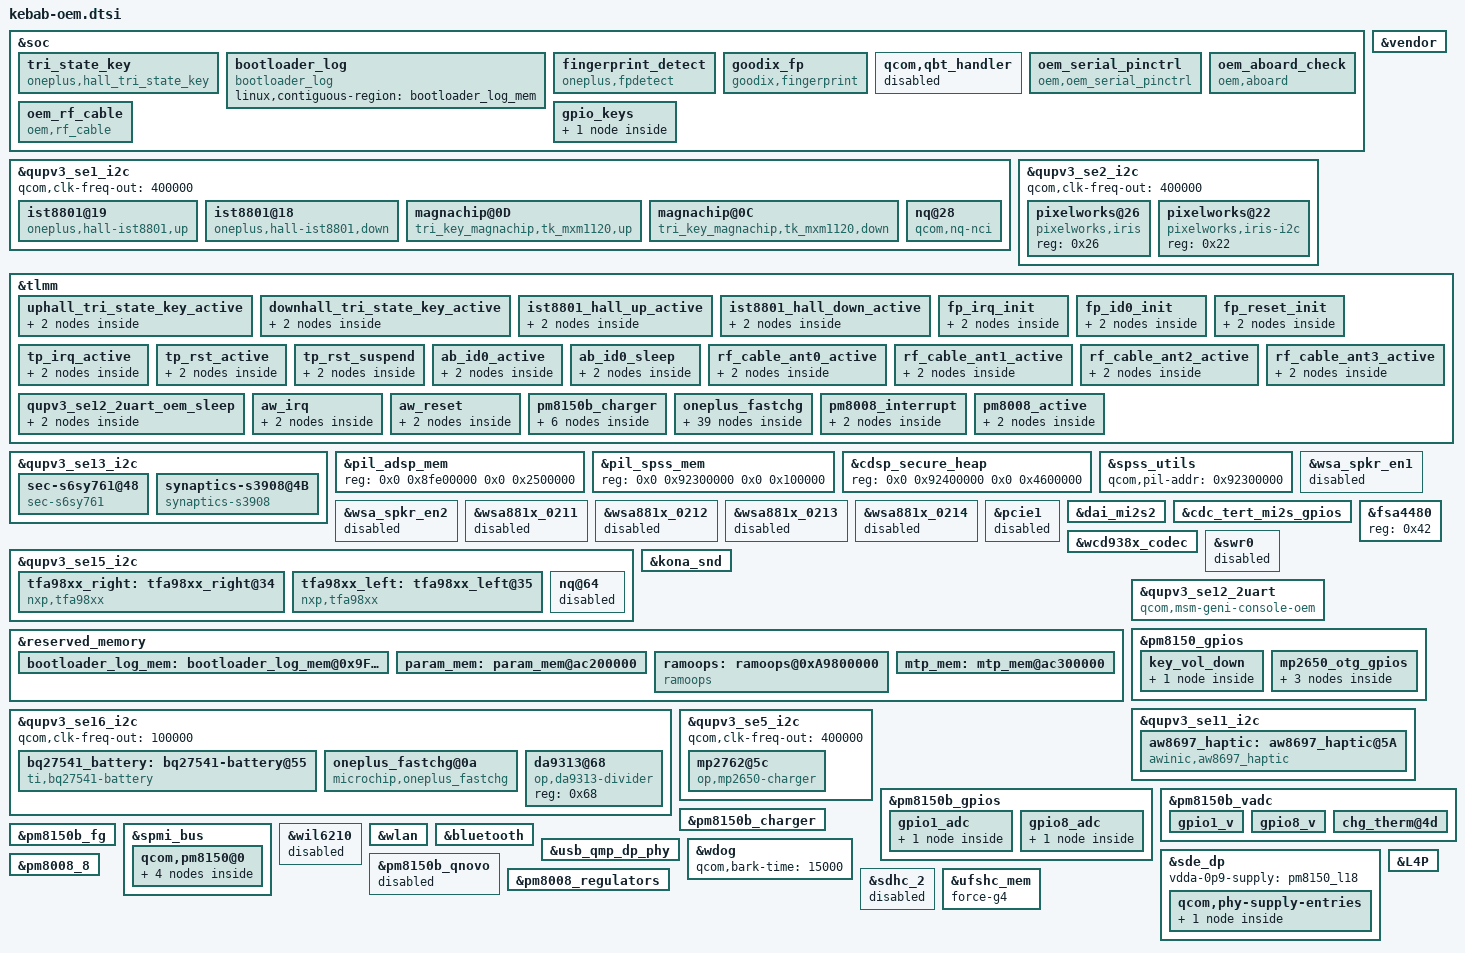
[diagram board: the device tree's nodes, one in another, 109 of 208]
/*this is for oem project dtsi*/
&soc {
	tri_state_key:tri_state_key {
		compatible = "oneplus,hall_tri_state_key";
		status = "ok";
		interrupt-parent = <&tlmm>;
		project_info = <1>;
	};

	bootloader_log {
		compatible = "bootloader_log";
		linux,contiguous-region = <&bootloader_log_mem>;
	};

	fingerprint_detect:fingerprint_detect {
		oneplus,19805;
		compatible = "oneplus,fpdetect";
		fp-gpio-id0 = <&tlmm 77 0>;
		pinctrl-names = "fp_id_init";
		pinctrl-0 = <&fp_id0_init>;
	};

	goodix_fp:goodix_fp {
		compatible = "goodix,fingerprint";
		interrupt-parent = <&tlmm>;
		//vdd-3v2-supply = <&pm8998_l22>;
		//vdd-voltage = <3200000 3200000>;
		//vdd-current = <50000>;
		fp-gpio-irq = <&tlmm 23 0x00>;
		fp-gpio-reset = <&tlmm 68 0x00>;
		fppower-supply = <&pm8150_l16>; 
		status = "okay";
	};

	qcom,qbt_handler {
		status = "disabled";
	};
};

&vendor {
	/delete-node/ extcon_usb1;
};


&qupv3_se1_i2c {
	status = "ok";
	qcom,clk-freq-out = <400000>;
	ist8801@19 {
		compatible = "oneplus,hall-ist8801,up";
		reg = <0x19>;
		dhall,id = <1>;
		vdd-supply = <&pm8150a_l10>;
		interrupt-parent = <&tlmm>;
		interrups = <157 0x02>;
		dhall,irq-gpio = <&tlmm 157 0x2008>;
		pinctrl-names = "ist8801_hall_up_active";
		pinctrl-0 = <&ist8801_hall_up_active>;
	};
	ist8801@18 {
		compatible = "oneplus,hall-ist8801,down";
		reg = <0x18>;
		dhall,id = <2>;
		vdd-supply = <&pm8150a_l10>;
		interrupt-parent = <&tlmm>;
		interrups = <158 0x02>;
		dhall,irq-gpio = <&tlmm 158 0x2008>;
		pinctrl-names = "ist8801_hall_down_active";
		pinctrl-0 = <&ist8801_hall_down_active>;
	};
};
&qupv3_se1_i2c {
	status = "ok";
	qcom,clk-freq-out = <400000>;
	magnachip@0D {
		compatible = "tri_key_magnachip,tk_mxm1120,up";
		reg = <0x0D>;
		vdd-supply = <&pm8150a_l10>;
		magnachip,init-interval = <200>;
		interrupt-parent = <&tlmm>;
		interrups = <157 0x02>;
		dhall,irq-gpio = <&tlmm 157 0x2008>;
		pinctrl-names = "uphall_tri_state_key_active";
		pinctrl-0 = <&uphall_tri_state_key_active>;
	};
	magnachip@0C {
		compatible = "tri_key_magnachip,tk_mxm1120,down";
		reg = <0x0C>;
		vdd-supply = <&pm8150a_l10>;
		magnachip,init-interval = <200>;
		interrupt-parent = <&tlmm>;
		interrups = <158 0x02>;
		dhall,irq-gpio = <&tlmm 158 0x2008>;
		pinctrl-names = "downhall_tri_state_key_active";
		pinctrl-0 = <&downhall_tri_state_key_active>;
	};
};

&qupv3_se2_i2c {
       status = "ok";
       qcom,clk-freq-out = <400000>;
       pixelworks@26 {  //i2c: 22, i3c: 26
               status = "ok";
               compatible = "pixelworks,iris";
               reg = <0x26>;
        };

       pixelworks@22 {  //i2c: 22, i3c: 26
               status = "ok";
               compatible = "pixelworks,iris-i2c";
               reg = <0x22>;
        };
};


&tlmm {
	uphall_tri_state_key_active: uphall_tri_state_key_active {
		mux {
			pins = "gpio157";
			function = "gpio";
		};
		config {
			pins = "gpio157";
			drive-strength = <2>;
			bias-pull-up;
		};
	};
	downhall_tri_state_key_active: downhall_tri_state_key_active {
		mux {
			pins = "gpio158";
			function = "gpio";
		};
		config {
			pins = "gpio158";
			drive-strength = <2>;
			bias-pull-up;
		};
	};
};
&tlmm {
	ist8801_hall_up_active: ist8801_hall_up_active {
		mux {
			pins = "gpio157";
			function = "gpio";
		};
		config {
			pins = "gpio157";
			drive-strength = <2>;
			bias-pull-up;
		};
	};
	ist8801_hall_down_active: ist8801_hall_down_active {
		mux {
			pins = "gpio158";
			function = "gpio";
		};
		config {
			pins = "gpio158";
			drive-strength = <2>;
			bias-pull-up;
		};
	};

	fp_irq_init: fp_irq_init {
		mux {
			pins = "gpio23";
			function = "gpio";
		};

		config {
			pins = "gpio23";
			drive-strength = <2>;
			bias-disable;
			input-enable;
		};
	};

	fp_id0_init: fp_id0_init {
		mux {
			pins = "gpio77";
			function = "gpio";
		};

		config {
			pins = "gpio77";
			drive-strength = <2>;
			bias-disable; /* No Pull */
			input-enable;
		};
	};

	fp_reset_init: fp_reset_init {
		mux {
			pins = "gpio131";
			function = "gpio";
		};

		config {
			pins = "gpio131";
			drive-strength = <8>;
			bias-pull-up;
		};
	};
};
&qupv3_se13_i2c {
	status = "ok";
	sec-s6sy761@48 {
		compatible = "sec-s6sy761";
		reg = <0x48>;
		project-name = "19811";
		chip-name = "SY761";
		module_id = <7>;
		reset-gpio = <&tlmm 38 0x00>;
		irq-gpio = <&tlmm 39 0x2008>;
		vdd_2v8-supply = <&pm8150_l13>;                 //set 3.3 by ldo
		vdd_2v8_volt = <3008000>;
		vcc_1v8-supply = <&pm8150a_l1>;
	//	enable1v8_gpio = <&tlmm 119 0x00>;               //set 1.8v by
		touchpanel,display-coords = <1439 3119>;
		touchpanel,panel-coords = <1439 3119>;
		touchpanel,tx-rx-num = <17 37>;
		//edge_limit_support = <1>;
		//spurious_fingerprint_support = <1>;
		//charger_pump_support = <1>;
		black_gesture_support = <1>;
		//black_gesture_test_support = <1>;
		game_switch_support = <1>;
		face_detect_support = <1>;
		touch_hold_support = <1>;
		touchpanel,max-num-support = <10>;
		charge_detect_support = <1>;
		//lcd_trigger_fp_check = <1>;
		module_id_support = <1>;
		pinctrl-names = "pin_set_high", "pin_set_low";
		pinctrl-0 = <&tp_irq_active &tp_rst_active>;
		pinctrl-1 = <&tp_rst_suspend>;
		//touchpanel,int-mode = <1>;
	};
};
&qupv3_se13_i2c {
	status = "ok";
	synaptics-s3908@4B {
		compatible = "synaptics-s3908";
		reg = <0x4B>;
		project-name = "19805";
		chip-name = "S3908";
		module_id = <7>;
		reset-gpio = <&tlmm 38 0x00>;
		irq-gpio = <&tlmm 39 0x2008>;
		vdd_2v8-supply = <&pm8150_l13>;                 //set 3.3 by ldo
		vdd_2v8_volt = <3008000>;
		vcc_1v8-supply = <&pm8150a_l1>;
		touchpanel,display-coords = <1079 2399>;
		touchpanel,panel-coords = <1079 2399>;
		touchpanel,tx-rx-num = <16 36>;
		//edge_limit_support = <1>;
		//spurious_fingerprint_support = <1>;
		//charger_pump_support = <1>;
		black_gesture_support = <1>;
		//black_gesture_test_support = <1>;
		game_switch_support = <1>;
		lcd_refresh_rate_switch = <1>;
		charge_detect_support = <1>;
		face_detect_support = <1>;
		touch_hold_support = <1>;
		touchpanel,max-num-support = <10>;
		report_flow_unlock_support = <1>;
		pinctrl-names = "pin_set_high", "pin_set_low";
		pinctrl-0 = <&tp_irq_active &tp_rst_active>;
		pinctrl-1 = <&tp_rst_suspend>;
		touchpanel,int-mode = <1>;
		panel = <&dsi_boe_nt37800_fhd_dsc_cmd &dsi_samsung_dd305_dsc_cmd &dsi_samsung_amb655x_dsc_cmd>;
	};
};
&tlmm {
	tp_irq_active: tp_irq_active {
		mux {
			pins = "gpio39";
			function = "gpio";
		};
		config {
			pins = "gpio39";
			drive-strength = <8>;
			bias-disable;
			input-enable;
		};
	};
	tp_rst_active: tp_rst_active {
		mux {
			pins = "gpio38";
			function = "gpio";
		};
		config {
			pins = "gpio38";
			drive-strength = <8>;
			bias-pull-up;
		};
	};
	tp_rst_suspend: tp_rst_suspend {
		mux {
			pins = "gpio38";
			function = "gpio";
		};
		config {
			pins = "gpio38";
			drive-strength = <8>;
			bias-pull-down;
		};
	};
};

&pil_adsp_mem {
	reg = <0x0 0x8fe00000 0x0 0x2500000>;
};

&pil_spss_mem {
	reg = <0x0 0x92300000 0x0 0x100000>;
};

&cdsp_secure_heap {
	reg = <0x0 0x92400000 0x0 0x4600000>;
};

&spss_utils {
	qcom,pil-addr = <0x92300000>; // backward compatible
};

&wsa_spkr_en1 {
	status = "disabled";
};

&wsa_spkr_en2 {
	status = "disabled";
};

&wsa881x_0211 {
	status = "disabled";
};

&wsa881x_0212 {
	status = "disabled";
};

&wsa881x_0213 {
	status = "disabled";
};

&wsa881x_0214 {
	status = "disabled";
};

&pcie1 {
    status = "disabled";
};

&qupv3_se15_i2c {
	tfa98xx_right: tfa98xx_right@34 {
		compatible = "nxp,tfa98xx";
		reg = <0x34>;
		reset-gpio = <&tlmm 91 0>;
		nxp,sb-ver-3P5 = <1>;
		status = "ok";
	};

	tfa98xx_left: tfa98xx_left@35 {
		compatible = "nxp,tfa98xx";
		reg = <0x35>;
		reset-gpio = <&tlmm 99 0>;
		nxp,sb-ver-3P5 = <1>;
		status = "ok";
	};

	nq@64 {
		status = "disabled";
	};
};

&dai_mi2s2 {
	qcom,msm-mi2s-rx-lines = <2>;
	qcom,msm-mi2s-tx-lines = <1>;
};

&cdc_tert_mi2s_gpios {
	pinctrl-0 = <&tert_mi2s_sck_active &tert_mi2s_ws_active
			&tert_mi2s_sd0_active &tert_mi2s_sd1_active>;
	pinctrl-1 = <&tert_mi2s_sck_sleep &tert_mi2s_ws_sleep
			&tert_mi2s_sd0_sleep &tert_mi2s_sd1_sleep>;
};

&fsa4480 {
	reg = <0x42>;
};

&wcd938x_codec {
	qcom,cdc-vdd-mic-bias-voltage = <3300000 3600000>;
	qcom,cdc-micbias2-mv = <2700>;
};

&swr0 {
	status = "disabled";
};

&kona_snd {
	//enable low-latency loopback
	asoc-platform = <&pcm0>, <&pcm1>, <&pcm2>, <&voip>, <&voice>,
			<&loopback1>, <&compress>, <&hostless>,
			<&afe>, <&lsm>, <&routing>, <&compr>,
			<&pcm_noirq>;
	qcom,afe-rxtx-lb = <1>;
	// default audio routing for 3-mic
	qcom,audio-routing =
		"AMIC1", "MIC BIAS1",
		"MIC BIAS1", "Analog Mic1",
		"AMIC2", "MIC BIAS2",
		"MIC BIAS2", "Analog Mic2",
		"AMIC3", "MIC BIAS3",
		"MIC BIAS3", "Analog Mic3",
		"AMIC4", "MIC BIAS3",
		"MIC BIAS3", "Analog Mic4",
		"AMIC5", "MIC BIAS4",
		"MIC BIAS4", "Analog Mic5",
		"TX DMIC0", "MIC BIAS1",
		"MIC BIAS1", "Digital Mic0",
		"TX DMIC1", "MIC BIAS1",
		"MIC BIAS1", "Digital Mic1",
		"TX DMIC2", "MIC BIAS3",
		"MIC BIAS3", "Digital Mic2",
		"TX DMIC3", "MIC BIAS4",
		"MIC BIAS4", "Digital Mic3",
		"TX DMIC4", "MIC BIAS4",
		"MIC BIAS4", "Digital Mic4",
		"TX DMIC5", "MIC BIAS4",
		"MIC BIAS4", "Digital Mic5",
		"IN1_HPHL", "HPHL_OUT",
		"IN2_HPHR", "HPHR_OUT",
		"IN3_AUX", "AUX_OUT",
		"TX SWR_ADC0", "ADC1_OUTPUT",
		"TX SWR_ADC1", "ADC2_OUTPUT",
		"TX SWR_ADC2", "ADC3_OUTPUT",
		"TX SWR_ADC3", "ADC4_OUTPUT",
		"TX SWR_DMIC0", "DMIC1_OUTPUT",
		"TX SWR_DMIC1", "DMIC2_OUTPUT",
		"TX SWR_DMIC2", "DMIC3_OUTPUT",
		"TX SWR_DMIC3", "DMIC4_OUTPUT",
		"TX SWR_DMIC4", "DMIC5_OUTPUT",
		"TX SWR_DMIC5", "DMIC6_OUTPUT",
		"TX SWR_DMIC6", "DMIC7_OUTPUT",
		"TX SWR_DMIC7", "DMIC8_OUTPUT",
		"WSA SRC0_INP", "SRC0",
		"WSA_TX DEC0_INP", "TX DEC0 MUX",
		"WSA_TX DEC1_INP", "TX DEC1 MUX",
		"RX_TX DEC0_INP", "TX DEC0 MUX",
		"RX_TX DEC1_INP", "TX DEC1 MUX",
		"RX_TX DEC2_INP", "TX DEC2 MUX",
		"RX_TX DEC3_INP", "TX DEC3 MUX",
		"VA_AIF1 CAP", "VA_SWR_CLK",
		"VA_AIF2 CAP", "VA_SWR_CLK",
		"VA_AIF3 CAP", "VA_SWR_CLK",
		"VA MIC BIAS1", "Digital Mic0",
		"VA MIC BIAS1", "Digital Mic1",
		"VA MIC BIAS3", "Digital Mic2",
		"VA MIC BIAS4", "Digital Mic3",
		"VA MIC BIAS4", "Digital Mic4",
		"VA MIC BIAS4", "Digital Mic5",
		"VA DMIC0", "VA MIC BIAS1",
		"VA DMIC1", "VA MIC BIAS1",
		"VA DMIC2", "VA MIC BIAS3",
		"VA DMIC3", "VA MIC BIAS4",
		"VA DMIC4", "VA MIC BIAS4",
		"VA DMIC5", "VA MIC BIAS4",
		"VA SWR_ADC0", "VA_SWR_CLK",
		"VA SWR_ADC1", "VA_SWR_CLK",
		"VA SWR_ADC2", "VA_SWR_CLK",
		"VA SWR_ADC3", "VA_SWR_CLK",
		"VA SWR_MIC0", "VA_SWR_CLK",
		"VA SWR_MIC1", "VA_SWR_CLK",
		"VA SWR_MIC2", "VA_SWR_CLK",
		"VA SWR_MIC3", "VA_SWR_CLK",
		"VA SWR_MIC4", "VA_SWR_CLK",
		"VA SWR_MIC5", "VA_SWR_CLK",
		"VA SWR_MIC6", "VA_SWR_CLK",
		"VA SWR_MIC7", "VA_SWR_CLK",
		"VA SWR_ADC0", "ADC1_OUTPUT",
		"VA SWR_ADC1", "ADC2_OUTPUT",
		"VA SWR_ADC2", "ADC3_OUTPUT",
		"VA SWR_ADC3", "ADC4_OUTPUT",
		"VA SWR_MIC0", "DMIC1_OUTPUT",
		"VA SWR_MIC1", "DMIC2_OUTPUT",
		"VA SWR_MIC2", "DMIC3_OUTPUT",
		"VA SWR_MIC3", "DMIC4_OUTPUT",
		"VA SWR_MIC4", "DMIC5_OUTPUT",
		"VA SWR_MIC5", "DMIC6_OUTPUT",
		"VA SWR_MIC6", "DMIC7_OUTPUT",
		"VA SWR_MIC7", "DMIC8_OUTPUT";

	//change to NC
	qcom,msm-mbhc-hphl-swh = <0>;
	qcom,wsa-max-devs = <0>;
	qcom,wsa-devs;
	//qcom,codec-aux-devs = <-2>;

	//qcom,tert-mi2s-gpios = <&tert_mi2s_gpios>;
	qcom,msm-mbhc-usbc-audio-supported = <1>;
	qcom,msm-mbhc-use-usbc-detect = <1>;
	qcom,msm-mbhc-hs-mic-max-threshold-mv = <2550>;
};

&reserved_memory {

	bootloader_log_mem: bootloader_log_mem@0x9FFF7000 {
		reg = <0 0x9FFF7000 0 0x00009000>;
		label = "bootloader_log_mem";
	};

	param_mem: param_mem@ac200000 {
		reg = <0 0xAC200000 0 0x00100000>;
		label = "param_mem";
	};

	/*after cdsp_secure_heap we add a offset to ignore change address need reconfig*/
	ramoops: ramoops@0xA9800000 {
		compatible = "ramoops";
		reg = <0 0xA9800000 0 0x00400000>;
		record-size =  <0x40000>; //256x1024
		console-size = <0x40000>;
		ftrace-size =  <0x40000>;
		pmsg-size=	   <0x200000>;
		devinfo-size=  <0x01000>;
		ecc-size=	   <0x0>;
	};

	mtp_mem: mtp_mem@ac300000 {
		reg = <0 0xAC300000 0 0x00B00000>;
		label = "mtp_mem";
	};
};

&qupv3_se1_i2c {
	status = "ok";
	qcom,clk-freq-out = <400000>;
	#address-cells = <1>;
	#size-cells = <0>;
	nq@28 {
		compatible = "qcom,nq-nci";
		reg = <0x28>;
		qcom,nq-irq = <&tlmm 111 0x00>;
		qcom,nq-ven = <&tlmm 83 0x00>;
		qcom,nq-firm = <&tlmm 110 0x00>;
		qcom,nq-clkreq = <&tlmm 7 0x00>;
		interrupt-parent = <&tlmm>;
		interrupts = <111 0>;
		interrupt-names = "nfc_irq";
		pinctrl-names = "nfc_active", "nfc_suspend";
		pinctrl-0 = <&nfc_int_active &nfc_enable_active
				&nfc_clk_req_active>;
		pinctrl-1 = <&nfc_int_suspend &nfc_enable_suspend
				&nfc_clk_req_suspend>;
	};
};

&qupv3_se12_2uart {
    compatible = "qcom,msm-geni-console-oem";
};
&soc {
     oem_serial_pinctrl {
        compatible = "oem,oem_serial_pinctrl";
        pinctrl-names = "uart_pinctrl_active","uart_pinctrl_deactive";
        pinctrl-0 = <&qupv3_se12_2uart_active>;
        pinctrl-1 = <&qupv3_se12_2uart_oem_sleep>;
    };

	oem_aboard_check:oem_aboard_check {
		compatible = "oem,aboard";
		interrupt-parent = <&tlmm>;
		oem,aboard-gpio-0 = <&tlmm 26 0>;
		pinctrl-names = "oem_aboard_active","oem_aboard_sleep";
		pinctrl-0 = <&ab_id0_active>;
        pinctrl-1 = <&ab_id0_sleep>;
	};

	oem_rf_cable:oem_rf_cable {
		compatible = "oem,rf_cable";
		interrupt-parent = <&tlmm>;
		rf,cable-gpio-0 = <&tlmm 109 0>;
		rf,cable-gpio-1 = <&tlmm 162 0>;
		rf,cable-gpio-2 = <&tlmm 175 0>;
		rf,cable-gpio-3 = <&tlmm 129 0>;
		rf,cable-support-timer = <0>;
		oem,rf_uevent_feature_enable;
		pinctrl-names = "oem_rf_cable_active";
		pinctrl-0 = <&rf_cable_ant0_active &rf_cable_ant1_active &rf_cable_ant2_active &rf_cable_ant3_active>;
	};

};

&tlmm {
    ab_id0_active: ab_id0_active {
        mux {
            pins = "gpio26";
            function = "gpio";
        };
        config {
            pins = "gpio26";
            drive-strength = <2>;
            bias-pull-up;
        };
    };
    ab_id0_sleep: ab_id0_sleep {
        mux {
            pins = "gpio26";
            function = "gpio";
        };
        config {
            pins = "gpio26";
            drive-strength = <2>;
            bias-disable;
        };
    };
    rf_cable_ant0_active: rf_cable_ant0_active {
        mux {
            pins = "gpio109";
            function = "gpio";
        };
        config {
            pins = "gpio109";
            drive-strength = <2>;
            bias-pull-up;
        };
    };
    rf_cable_ant1_active: rf_cable_ant1_active {
        mux {
            pins = "gpio162";
            function = "gpio";
        };
        config {
            pins = "gpio162";
            drive-strength = <2>;
            bias-pull-up;
        };
    };
    rf_cable_ant2_active: rf_cable_ant2_active {
        mux {
            pins = "gpio175";
            function = "gpio";
        };
        config {
            pins = "gpio175";
            drive-strength = <2>;
            bias-pull-up;
        };
    };
    rf_cable_ant3_active: rf_cable_ant3_active {
        mux {
            pins = "gpio129";
            function = "gpio";
        };
        config {
            pins = "gpio129";
            drive-strength = <2>;
            bias-pull-up;
        };
    };
    qupv3_se12_2uart_oem_sleep: qupv3_se12_2uart_oem_sleep {
        mux {
            pins = "gpio34", "gpio35";
            function = "gpio";
        };
        config {
            pins = "gpio34", "gpio35";
            drive-strength = <2>;
            bias-pull-down;
        };
    };
};

&pm8150_gpios {
	key_vol_down {
		key_vol_down_default: key_vol_down_default {
			pins = "gpio7";
			function = "normal";
			input-enable;
			bias-pull-up;
			power-source = <1>;
		};
	};
};
&soc {
	gpio_keys {
		pinctrl-0 = <&key_vol_up_default &key_vol_down_default>;
		vol_down {
			label = "volume_down";
			gpios = <&pm8150_gpios 7 GPIO_ACTIVE_LOW>;
			linux,input-type = <1>;
			linux,code = <KEY_VOLUMEDOWN>;
			gpio-key,wakeup;
			debounce-interval = <15>;
			linux,can-disable;
		};
	};
};

&qupv3_se11_i2c {
		status = "ok";
		aw8697_haptic:aw8697_haptic@5A {
		compatible = "awinic,aw8697_haptic";
		reg = <0x5A>;
		reset-gpio = <&tlmm 72 0x00>;
		irq-gpio = <&tlmm 11 0x00>;
		pinctrl-names = "default";
		pinctrl-0 = <&aw_irq &aw_reset>;
		status = "okay";
   };
};

&tlmm {
       aw_irq: aw_irq {
	       mux {
	            pins = "gpio11";
	            function = "gpio";
	       };
	       config {
	               pins = "gpio11";
	               drive-strength = <2>;
	               bias-pull-up;
	       };
       };
       aw_reset: aw_reset {
	       mux {
	            pins = "gpio72";
	            function = "gpio";
	       };
	      config {
	              pins = "gpio72";
	              drive-strength = <2>;
	              bias-disable;
	      };
      };
};

/* @bsp, 2019/07/08 Battery & Charging porting STRAT */
&qupv3_se16_i2c {
	qcom,clk-freq-out = <100000>;
	status = "ok";
	bq27541_battery:bq27541-battery@55 {
		status = "ok";
		compatible = "ti,bq27541-battery";
		reg = <0x55>;
		qcom,modify-soc-smooth;
		op,batt_bq28z610;
	};

	oneplus_fastchg@0a{
		status = "ok";
		compatible = "microchip,oneplus_fastchg";
		reg = <0x0a>;
		interrupt-parent = <&tlmm>;
		interrupts = <158 IRQ_TYPE_EDGE_RISING>;
		microchip,mcu-en-gpio = <&tlmm 10 0x00>;
		microchip,usb-on = <&tlmm 47 0x00>;
		microchip,usb-on_46 = <&tlmm 46 0x00>;
		microchip,usb-sw-1-gpio = <&tlmm 82 0x00>;
		microchip,usb-sw-2-gpio = <&tlmm 141 0x00>;
		microchip,ap-clk = <&tlmm 54 0x00>;
		microchip,ap-data = <&tlmm 55 0x00>;
		microchip,id-m0 = <&tlmm 50 0x00>;

		pinctrl-names = "mux_fastchg_active",
			"mux_fastchg_suspend",
			"mcu_data_write",
			"mcu_data_read",
			"mcu_id_hiz",
			"mcu_id_pull_up",
			"mcu_id_pull_down";
		pinctrl-0 = <&fastchg_active
			&usb_on_active
			&usb_sw_active
			&ap_clk_active>;
		pinctrl-1 = <&usb_sw_suspend
			&usb_on_suspend
			&fastchg_suspend
			&ap_clk_suspend>;
		pinctrl-2 = <&ap_data_write>;
		pinctrl-3 = <&ap_data_read>;
		pinctrl-4 = <&mcu_id_hiz>;
		pinctrl-5 = <&mcu_id_pull_up>;
		pinctrl-6 = <&mcu_id_pull_down>;
		op,fw-erase-count = <384>;
		op,fw-addr-low = <0x88>;
		op,fw-addr-high = <0>;
	};
	da9313@68 {
		status = "ok";
		compatible = "op,da9313-divider";
		reg = <0x68>;
	};
};

&qupv3_se5_i2c {
	status= "ok";
	qcom,clk-freq-out = <400000>;
	mp2762@5c {
		status = "ok";
		compatible = "op,mp2650-charger";
		reg = <0x5c>;
		mp,mps_otg_en-gpio = <&pm8150_gpios 3 0x00>;
		pinctrl-names = "mps_otg_en_active", "mps_otg_en_sleep",
				"mps_otg_en_default";
		pinctrl-0 = <&mps_otg_en_active>;
		pinctrl-1 = <&mps_otg_en_sleep>;
		pinctrl-2 = <&mps_otg_en_default>;
	};
};
&pm8150_gpios {
	mp2650_otg_gpios {
		mps_otg_en_active: mps_otg_en_active {
			pins = "gpio3"; /* GPIO 3 */
			function = "normal"; /* normal */
			bias-disable; //No Pull
			power-source = <1>;//VIN1 1.8
			output-high; //digital output, no invert
			qcom,drive-strength = <3>; //LOW strength
			//drive-push-pull;//CMOS
		};
		mps_otg_en_sleep: mps_otg_en_sleep {
			pins = "gpio3"; /* GPIO 3 */
			function = "normal"; /* normal */
			bias-disable; //No Pull
			power-source = <1>;//VIN1 1.8
			output-low; //digital output, no invert
			qcom,drive-strength = <3>; //LOW strength
			//drive-push-pull;//CMOS
		};
		mps_otg_en_default: mps_otg_en_default {
			pins = "gpio3"; /* GPIO 3 */
			function = "normal"; /* normal */
			bias-disable; //No Pull
			power-source = <1>;//VIN1 1.8
			output-low; //digital output, no invert
			qcom,drive-strength = <3>; //LOW strength
			//drive-push-pull;//CMOS
		};
	};
};
&pm8150b_gpios {
	gpio1_adc {
		gpio1_adc_default: gpio1_adc_default {
			pins = "gpio1"; /* GPIO 1 */
			function = "normal"; /* normal */
			bias-pull-up;
			bias-high-impedance; /* DISABLE GPIO1 for ADC*/
		};
	};

	gpio8_adc {
		gpio8_adc_default: gpio8_adc_default {
			pins = "gpio8"; /* GPIO 8 */
			function = "normal"; /* normal */
			bias-pull-up;
			bias-high-impedance; /* DISABLE GPIO8 for ADC*/
		};
	};
};

&pm8150b_vadc {
	gpio1_v {
		reg = <ADC_AMUX_THM4_PU1>;/* 0x30*/
		label = "gpio1_v";
		qcom,ratiometric;
		qcom,hw-settle-time = <800>;
		qcom,pre-scaling = <1 1>;
	};

	gpio8_v {
		reg = <ADC_GPIO4_PU1>;
		label = "gpio8_v";
		qcom,hw-settle-time = <800>;
		qcom,ratiometric;
		qcom,pre-scaling = <1 1>;
	};

	chg_therm@4d {
		reg = <ADC_AMUX_THM1_PU2>;
		label = "chg_therm";
		qcom,hw-settle-time = <200>;
		qcom,ratiometric;
		qcom,pre-scaling = <1 1>;
	};
};

&pm8150b_charger {
	qcom,dc-icl-ua = <1200000>;
	qcom,fcc-max-ua = <3000000>;
	qcom,usb-icl-ua = <1800000>;
	qcom,fv-max-uv = <4455000>;
	/* ibatmax setting for different temp regions */
	ibatmax-little-cold-ma = <350>;
	ibatmax-cool-ma = <2000>;
	ibatmax-little-cool-ma = <2000>;
	ibatmax-pre-normal-ma = <2000>;
	ibatmax-normal-ma = <2000>;
	ibatmax-warm-ma = <1100>;
	ibatmax-little-cool-thr-ma = <1900>;
	ibatmax-cool-thr-ma = <1100>;
	/* vbatmax setting for different temp regions */
	vbatmax-little-cold-mv = <3975>;
	vbatmax-cool-mv = <4435>;
	vbatmax-little-cool-mv = <4435>;
	vbatmax-pre-normal-mv = <4435>;
	vbatmax-normal-mv = <4435>;
	vbatmax-warm-mv = <4130>;
	little-cool-vbat-thr-mv = <4180>;
	cool-vbat-thr-mv = <4180>;
	/* vbatdet setting for different temp regions */
	vbatdet-little-cold-mv = <3675>;
	vbatdet-cool-mv = <4235>;
	vbatdet-little-cool-mv = <4335>;
	vbatdet-pre-normal-mv = <4335>;
	vbatdet-normal-mv = <4335>;
	vbatdet-warm-mv = <4030>;
	/* temp region settings */
	cold-bat-decidegc = <20>;
	little-cold-bat-decidegc = <0>;
	cool-bat-decidegc = <50>;
	little-cool-bat-decidegc = <120>;
	pre-normal-bat-decidegc = <160>;
	warm-bat-decidegc = <450>;
	hot-bat-decidegc = <500>;
	qcom,otg-cl-ua = <1500000>;
	op,sw-iterm-ma = <115>;
	op,sw-check-full-enable;
	/* pd & qc config */
	qcom,op-pps-usbpd-detection = <&pm8150b_pdphy>;
	op,pd-support9v-enable;
	op,support-hvdcp;
	op,pdqc-to-5v-vbat-thr = <4100>;
	op,pdqc-9v-vbat-thr = <4000>;
	/*ffc temp region*/
	ffc-pre-normal-decidegc = <120>;
	ffc-normal-decidegc = <350>;
	ffc-warm-decidegc = <400>;
	ffc-normal-fcc-ma = <650>;
	ffc-warm-fcc-ma = <750>;
	ffc-normal-cutoff-ma = <550>;
	ffc-warm-cutoff-ma = <650>;
	ffc-full-vbat-mv = <4475>;

	/delete-property/ qcom,sw-jeita-enable;

	/*otg low battery current limit*/
	op,otg-icl-ctrl-enable;
	otg-low-battery-thr = <15>;
	otg-low-bat-icl-thr = <1000000>;
	otg-normal-bat-icl-thr = <1500000>;

	/* for usb connecter temperature check */
	op,normal-check-interval-period = <300>;
	op,fast-check-interval-period = <50>;
	op,fast-check-threshold-temp = <33>;
	op,high-temp-short-check-timeout = <1500>;
	op,first-protect-connecter-temp = <60>;
	op,second-protect-connecter-temp = <45>;
	op,second-protect-interval-temp = <14>;
	op,third-protect-rise-rate = <3>;
	op,third-protect-loop-temp = <40>;
	op,third-protect-interval-temp = <8>;
	op,third-protect-base-temp = <20>;

	/* for charge current&voltage curve optimize */
	op,fv-offset-voltage-mv = <50>;

	/* for 4p45v not charge full issue add sw full count numb */
	op,full-count-sw-numb = <2>;

	/* other settings */
	/*disable lpd*/
	qcom,lpd-disable;
	qcom,cutoff-voltage-with-charger = <3250>;
	qcom,msm-bus,name = "dash_clk_vote";
	qcom,msm-bus,num-cases = <2>;
	qcom,msm-bus,num-paths = <1>;
	qcom,msm-bus,vectors-KBps = <1 731 0 300000000>,
					<1 731 0 0>;
	op,support-sdram-store-soc;
	/* for external ship mode suppot */
	op,stm-ctrl-gpio = <&tlmm 22 0x00>;
	pinctrl-names = "op_ship_mode_default",
					"op_usb_temp_adc_default",
					"op_usb_temp_adc_sec",
					"default";
	pinctrl-0 = <&ship_mode_default>;
	pinctrl-1 = <&gpio1_adc_default>;
	pinctrl-2 = <&gpio8_adc_default>;
	pinctrl-3 = <&usb_detect_default>;

	/*usb connector hw auto detection*/
	op,usb-check = <&tlmm 14 0x00>;
	/* for usb connector temp protect */
	op,low-voltage-charger;
	io-channels = <&pm8150b_vadc ADC_MID_CHG_DIV6>,
				<&pm8150b_vadc ADC_USB_IN_V_16>,
				<&pm8150b_vadc ADC_USB_IN_I>,
				<&pm8150b_vadc ADC_SBUx>,
				<&pm8150b_vadc ADC_VPH_PWR>,
				<&pm8150b_vadc ADC_CHG_TEMP>,
				<&pm8150b_vadc ADC_AMUX_THM4_PU1>,
				<&pm8150b_vadc ADC_GPIO4_PU1>,
				<&pm8150b_vadc ADC_AMUX_THM1_PU2>;
	io-channel-names = "mid_voltage",
				"usb_in_voltage",
				"usb_in_current",
				"sbux_res",
				"vph_voltage",
				"chg_temp",
				"gpio1_voltage",
				"gpio8_voltage",
				"skin_therm";

	op,vbus-ctrl-gpio = <&pm8150_gpios 9 GPIO_ACTIVE_LOW>;

	/delete-property/ qcom,fcc-stepping-enable;
};

&pm8150b_fg {
	qcom,fg-force-load-profile;
	oem,use_external_fg;
	qcom,fg-rsense-sel = <0>;
	qcom,fg-sys-term-current = <180>;
	qcom,fg-chg-term-current = <165>;
	qcom,fg-esr-calib-dischg;
	oem,iskebab;
};

&tlmm {
	pm8150b_charger {
		ship_mode_default: ship_mode_default {
			mux {
				pins = "gpio22";
				function = "gpio";
			};

			config {
				pins = "gpio22";
				drive-strength = <8>;
				bias-pull-down;
			};
		};

		usb_detect_default: usb_detect_default {
			mux {
				pins = "gpio14";
				function = "gpio";
			};

			config {
				pins = "gpio14";
				drive-strength = <8>;
				bias-pull-up;
			};
		};
	};

	oneplus_fastchg {
		usb_sw_active: usb_sw_active {
			mux {
				pins = "gpio82", "gpio141";
				function = "gpio";
			};

			config {
				pins = "gpio82", "gpio141";
				drive-strength = <16>;
				bias-pull-down;
			};
		};

		usb_sw_suspend: usb_sw_suspend {
			mux {
				pins = "gpio82", "gpio141";
				function = "gpio";
			};

			config {
				pins = "gpio82", "gpio141";
				drive-strength = <2>;
				bias-disable;
			};
		};

		usb_on_active: usb_on_active {
			mux {
				pins = "gpio47", "gpio46";
				function = "gpio";
			};

			config {
				pins = "gpio47", "gpio46";
				drive-strength = <16>;
				bias-pull-down;
			};
		};

		usb_on_suspend: usb_on_suspend {
			mux {
				pins = "gpio47", "gpio46";
				function = "gpio";
			};

			config {
				pins = "gpio47", "gpio46";
				drive-strength = <2>;
				bias-disable;
			};
		};

		fastchg_active: fastchg_active {
			mux {
				pins = "gpio10";
				function = "gpio";
			};

			config {
				pins = "gpio10";
				drive-strength = <16>;
				bias-pull-down;
			};
		};

		fastchg_suspend: fastchg_suspend {
			mux {
				pins = "gpio10";
				function = "gpio";
			};

			config {
				pins = "gpio10";
				drive-strength = <2>;
				bias-disable;
			};
		};

		ap_clk_active: ap_clk_active {
			mux {
				pins = "gpio54";
				function = "gpio";
			};

			config {
				pins = "gpio54";
				drive-strength = <16>;
				bias-pull-up;
			};
		};

		ap_clk_suspend: ap_clk_suspend {
			mux {
				pins = "gpio54";
				function = "gpio";
			};

			config {
				pins = "gpio54";
				drive-strength = <2>;
				bias-disable;
			};
		};

		ap_data_write: ap_data_write {
			mux {
				pins = "gpio55";
				function = "gpio";
			};

			config {
				pins = "gpio55";
				drive-strength = <16>;
				bias-pull-up;
			};
		};

		ap_data_read: ap_data_read {
			mux {
				pins = "gpio55";
				function = "gpio";
			};

			config {
				pins = "gpio55";
				drive-strength = <2>;
				bias-disable;
			};
		};
		mcu_id_hiz: mcu_id_hiz {
			mux {
				pins = "gpio50";
				function = "gpio";
			};

			config {
				pins = "gpio50";
				drive-strength = <2>;
				bias-disable;
				input-enable;
			};
		};
		mcu_id_pull_up: mcu_id_pull_up {
			mux {
				pins = "gpio50";
				function = "gpio";
			};

			config {
				pins = "gpio50";
				drive-strength = <2>;
				bias-pull-up;
				input-enable;
			};
		};
		mcu_id_pull_down: mcu_id_pull_down {
			mux {
				pins = "gpio50";
				function = "gpio";
			};

			config {
				pins = "gpio50";
				drive-strength = <2>;
				bias-pull-down;
				input-enable;
			};
		};
	};
};
/* @bsp, 2019/07/08 Battery & Charging porting END */

&spmi_bus {
	qcom,pm8150@0 {
		qcom,power-on@800 {
			interrupts = <0x0 0x8 0x0 IRQ_TYPE_EDGE_BOTH>,
			             <0x0 0x8 0x1 IRQ_TYPE_EDGE_BOTH>,
			             <0x0 0x8 0x5 IRQ_TYPE_EDGE_BOTH>;
			interrupt-names = "kpdpwr", "resin", "kpdpwr-resin-bark";
			qcom,s3-src = "kpdpwr-and-resin";

			qcom,pon_1 {
				qcom,support-reset = <0>;
				qcom,s1-timer = <6720>;
				qcom,s2-timer = <2000>;
				qcom,s2-type = <PON_POWER_OFF_TYPE_HARD_RESET>;
				qcom,pull-up;
			};

			qcom,pon_2 {
				qcom,support-reset = <0>;
				qcom,s1-timer = <6720>;
				qcom,s2-timer = <2000>;
				qcom,s2-type = <PON_POWER_OFF_TYPE_HARD_RESET>;
				qcom,pull-up;
			};

			qcom,pon_3 {
				qcom,pon-type = <PON_POWER_ON_TYPE_KPDPWR_RESIN>;
				qcom,support-reset = <0>;
				qcom,s1-timer = <6720>;
				qcom,s2-timer = <2000>;
				qcom,s2-type = <PON_POWER_OFF_TYPE_HARD_RESET>;
				qcom,pull-up;
			};
		};
	};
};

&wil6210 {
	status = "disabled";
};

&wlan {
	vdd-wlan-dig-supply = <&pm8150_s6>;
	qcom,vdd-wlan-dig-config = <950000 950000 0 0 1>;
	qcom,vdd-wlan-rfa1-config = <1900000 2040000 0 0 1>;
};

&bluetooth {
	qca,bt-vdd-dig-supply = <&pm8150_s6>;
	qca,bt-vdd-dig-voltage-level = <950000 950000>;
	qca,bt-vdd-rfa1-voltage-level = <1900000 2040000>;
};

/* @bsp, usb config START */
/* @bsp, As QRD-DVT have this config, keep the same config
 * for ldo18 power suspend
 */
&usb_qmp_dp_phy {
	vdd-supply = <&pm8150_l18>;
	qcom,vdd-voltage-level = <0 912000 912000>;
};

&sde_dp {
	vdda-0p9-supply = <&pm8150_l18>;
	qcom,phy-supply-entries {
		qcom,phy-supply-entry@0 {
			qcom,supply-min-voltage = <912000>;
			qcom,supply-max-voltage = <912000>;
		};
	};
};
/* @bsp, usb config END */

&wdog{
	qcom,bark-time = <15000>;
};

&pm8150b_qnovo {
	status = "disabled";
};

&qupv3_se2_i2c {
	status = "ok";
	#include "pm8008.dtsi"
};

&pm8008_regulators {
        vdd_l1_l2-supply = <&S8C>;

        vdd_l3_l4-supply = <&BOB>;

        vdd_l5-supply = <&BOB>;

        vdd_l6-supply = <&BOB>;

        vdd_l7-supply = <&BOB>;

};

&L4P {
       regulator-min-microvolt = <1800000>;
       regulator-max-microvolt = <1800000>;
};

&tlmm  {
	pm8008_interrupt: pm8008_interrupt {
		mux {
			pins = "gpio112";
			function = "gpio";
		};

		config {
			pins = "gpio112";
			bias-disable;
			input-enable;
		};
	};

	pm8008_active: pm8008_active {
		mux {
			pins = "gpio93";
			function = "gpio";
		};

		config {
			pins = "gpio93";
			bias-pull-up;
			output-high;
			drive-strength = <2>;
		};
	};
};

&pm8008_8 {
	/* PM8008 IRQ STAT */
	interrupt-parent = <&tlmm>;
	interrupts = <112 IRQ_TYPE_EDGE_RISING>;

	pinctrl-names = "default";
	pinctrl-0 = <&pm8008_active &pm8008_interrupt>;
};
&sdhc_2 {
	status = "disabled";
};

&ufshc_mem {
	force-g4;
};
